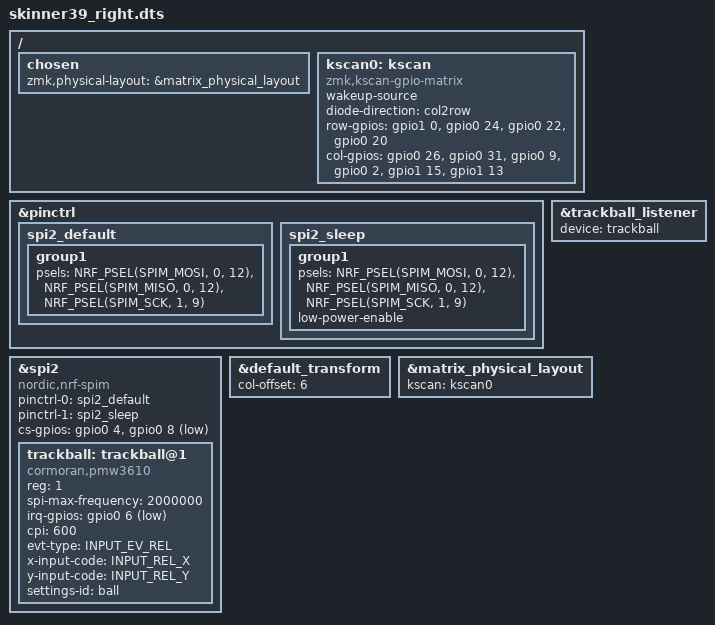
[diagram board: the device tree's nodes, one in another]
#include "skinner39.dtsi"
#include <dt-bindings/led/led.h>

&pinctrl {
    spi2_default: spi2_default {
				group1 {
						psels = <NRF_PSEL(SPIM_MOSI, 0, 12)>,
						<NRF_PSEL(SPIM_MISO, 0, 12)>,
						<NRF_PSEL(SPIM_SCK, 1, 9)>;
				};
		};
	
    spi2_sleep: spi2_sleep {
				group1 {
						psels = <NRF_PSEL(SPIM_MOSI, 0, 12)>,
						<NRF_PSEL(SPIM_MISO, 0, 12)>,
						<NRF_PSEL(SPIM_SCK, 1, 9)>;
						low-power-enable;
				};
		};
};

#define INPUT_EV_KEY 0x01               /**< Key event */
#define INPUT_EV_REL 0x02               /**< Relative coordinate event */
#define INPUT_EV_ABS 0x03               /**< Absolute coordinate event */
#define INPUT_EV_MSC 0x04               /**< Miscellaneous event */
#define INPUT_EV_VENDOR_START 0x30      /**< Vendor specific event start */
#define INPUT_EV_VENDOR_STOP 0x3e       /**< Vendor specific event stop */

#define INPUT_REL_X 0x00                /**< Relative X coordinate */
#define INPUT_REL_Y 0x01                /**< Relative Y coordinate */
#define INPUT_REL_WHEEL 0x08            /**< Relative wheel coordinate */
#define INPUT_REL_HWHEEL 0x06           /**< Relative horizontal wheel coordinate */
#define INPUT_REL_MISC 0x09             /**< Relative misc coordinate */


nice_view_spi: &spi2 {
    compatible = "nordic,nrf-spim";
    pinctrl-0 = <&spi2_default>;
    pinctrl-1 = <&spi2_sleep>;
    pinctrl-names = "default", "sleep";
    cs-gpios = <&gpio0 4 (GPIO_ACTIVE_HIGH | GPIO_PULL_DOWN) >,
							<&gpio0 8 GPIO_ACTIVE_LOW>;
		trackball: trackball@1 {
			status = "okay";
			// cormoran / DYA Studio compatible PMW3610 driver, the same
			// one used by the keyball dya-nv branch.
			compatible ="cormoran,pmw3610";
			reg = <1>;
			spi-max-frequency = <2000000>;
			irq-gpios = <&gpio0 6 (GPIO_ACTIVE_LOW | GPIO_PULL_UP)>;
			cpi = <600>;
			evt-type = <INPUT_EV_REL>;
			x-input-code = <INPUT_REL_X>;
			y-input-code = <INPUT_REL_Y>;
			// Readable key prefix for the runtime settings
			// ("cpi@ball", ...) shown in DYA Studio.
			settings-id = "ball";
	};
};

// The right half is the central and carries the trackball, so the ball is
// used locally here (and configured from DYA Studio on this same half).
&trackball_listener {
	status = "okay";
	device = <&trackball>;
};

&default_transform {
	col-offset = <6>;
};

&matrix_physical_layout {
  	kscan = <&kscan0>;
};

/ {
	chosen {
		zmk,physical-layout = &matrix_physical_layout;
	};
    kscan0: kscan {
        compatible = "zmk,kscan-gpio-matrix";
        wakeup-source;

        diode-direction = "col2row";
        row-gpios
            = <&gpio1 0 (GPIO_ACTIVE_HIGH | GPIO_PULL_DOWN)>
            , <&gpio0 24 (GPIO_ACTIVE_HIGH | GPIO_PULL_DOWN)>
            , <&gpio0 22 (GPIO_ACTIVE_HIGH | GPIO_PULL_DOWN)>
            , <&gpio0 20 (GPIO_ACTIVE_HIGH | GPIO_PULL_DOWN)>
            ;
			col-gpios
							= <&gpio0 26 (GPIO_ACTIVE_HIGH | GPIO_PULL_DOWN)>
							, <&gpio0 31 (GPIO_ACTIVE_HIGH | GPIO_PULL_DOWN)>
							, <&gpio0 9 (GPIO_ACTIVE_HIGH | GPIO_PULL_DOWN)>
							, <&gpio0 2 (GPIO_ACTIVE_HIGH | GPIO_PULL_DOWN)>
							, <&gpio1 15 (GPIO_ACTIVE_HIGH | GPIO_PULL_DOWN)> 
							, <&gpio1 13 (GPIO_ACTIVE_HIGH | GPIO_PULL_DOWN)>;
    };
};
